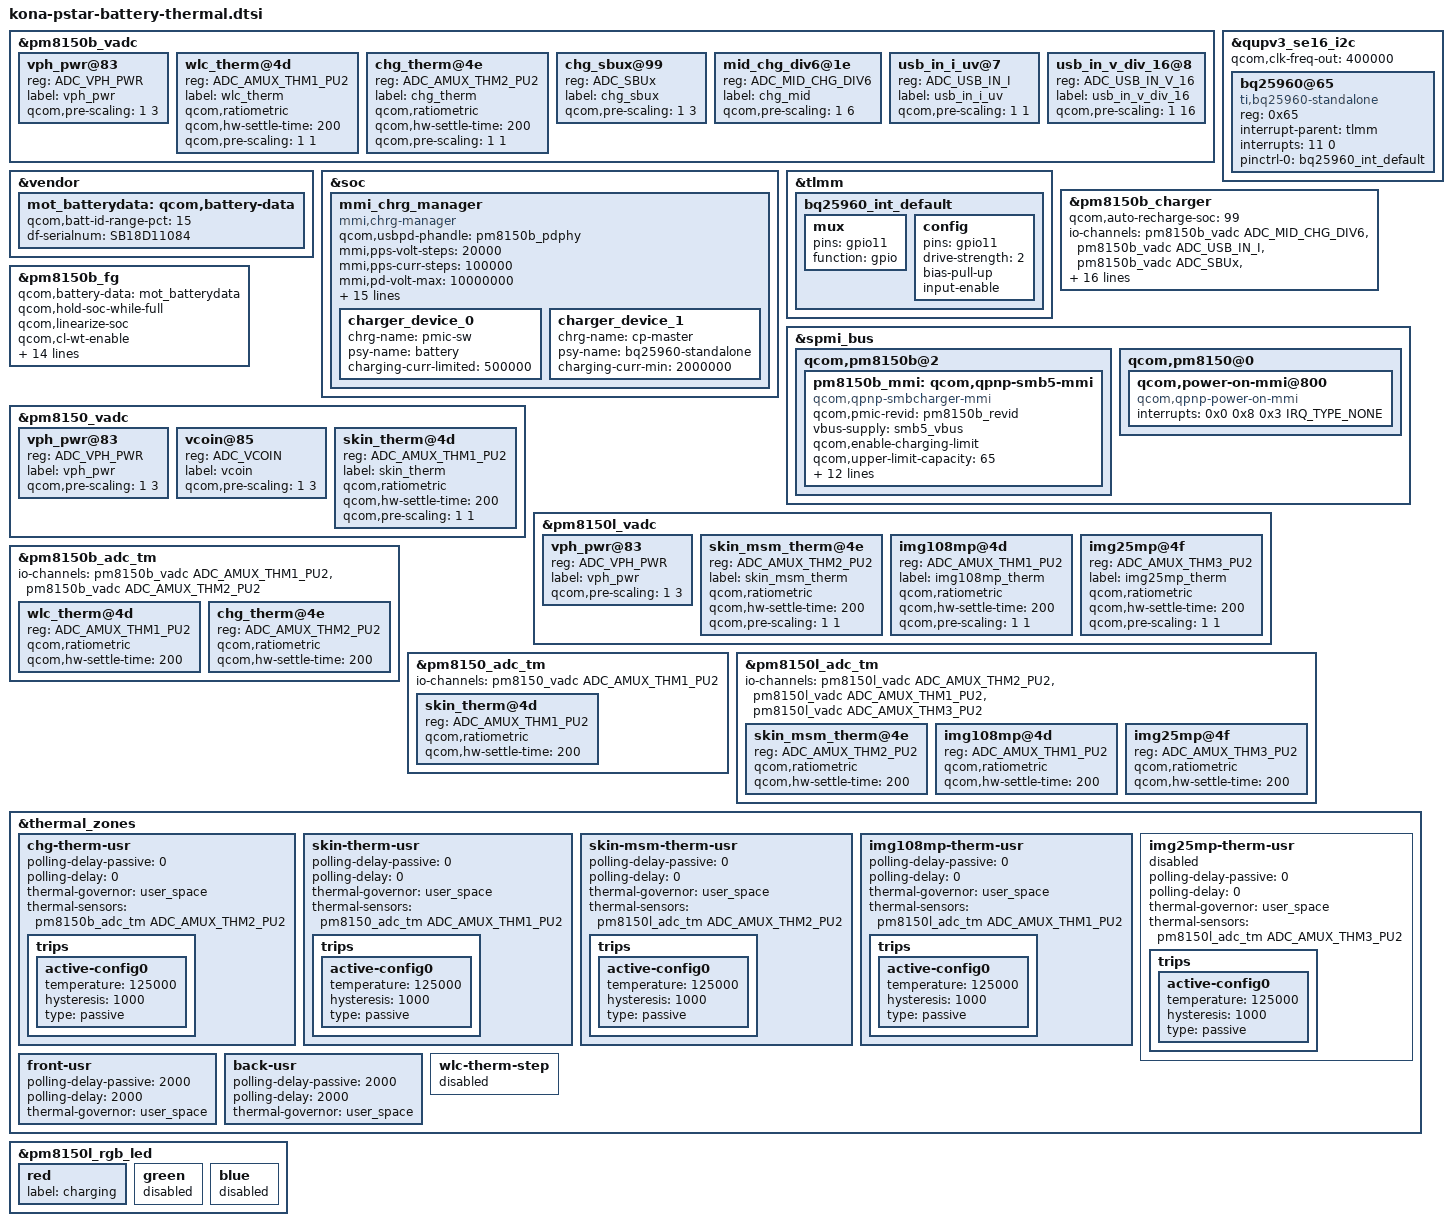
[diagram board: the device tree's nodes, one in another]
#include <dt-bindings/gpio/gpio.h>
#include <dt-bindings/pinctrl/qcom,pmic-gpio.h>

&pm8150b_vadc {
        #address-cells = <1>;
        #size-cells = <0>;

        vph_pwr@83 {
                reg = <ADC_VPH_PWR>;
                label = "vph_pwr";
                qcom,pre-scaling = <1 3>;
        };

        wlc_therm@4d {
                reg = <ADC_AMUX_THM1_PU2>;
                label = "wlc_therm";
                qcom,ratiometric;
                qcom,hw-settle-time = <200>;
                qcom,pre-scaling = <1 1>;
        };

        chg_therm@4e {
                reg = <ADC_AMUX_THM2_PU2>;
                label = "chg_therm";
                qcom,ratiometric;
                qcom,hw-settle-time = <200>;
                qcom,pre-scaling = <1 1>;
        };

        chg_sbux@99 {
                reg = <ADC_SBUx>;
                label = "chg_sbux";
                qcom,pre-scaling = <1 3>;
        };

        mid_chg_div6@1e {
                reg = <ADC_MID_CHG_DIV6>;
                label = "chg_mid";
                qcom,pre-scaling = <1 6>;
        };

        usb_in_i_uv@7 {
                reg = <ADC_USB_IN_I>;
                label = "usb_in_i_uv";
                qcom,pre-scaling = <1 1>;
        };

        usb_in_v_div_16@8 {
                reg = <ADC_USB_IN_V_16>;
                label = "usb_in_v_div_16";
                qcom,pre-scaling = <1 16>;
        };
};

&vendor {
        mot_batterydata: qcom,battery-data {
                qcom,batt-id-range-pct = <15>;
                df-serialnum = "SB18D11084";
		#include "fg-gen4-batterydata-MT45-4520mAh-Amperex.dtsi"
        };
};

&soc {
	mmi_chrg_manager {
		compatible = "mmi,chrg-manager";
		qcom,usbpd-phandle = <&pm8150b_pdphy>;
		mmi,pps-volt-steps = <20000>;
		mmi,pps-curr-steps = <100000>;
		mmi,pd-volt-max = <10000000>;
		mmi,pd-curr-max = <3000000>;
		mmi,batt-curr-boost = <300000>;
		mmi,batt-ovp-lmt = <4580000>;
		mmi,pl-chrg-vbatt-min = <3600000>;
		mmi,typec-middle-current = <1500000>;
		mmi,step-first-current-comp = <0>;
		mmi,dont-rerun-aicl;
		mmi,chrg-temp-zones-num = <5>;
		mmi,mmi-chrg-temp-zones =
					<0  4200 873  0 0 0 0>,
					<10 4250 2180 4480 873 0 0>,
					<15 4480 2180 0 0 0 0>,
					<45 4250 6000 4350 5200 4480 4000>,
					<60 4200 2180 0 0 0 0>;
		mmi,thermal-mitigation =
					<6000000>,
					<5000000>,
					<4000000>,
					<3000000>,
					<2000000>;
		charger_device_0 {
			chrg-name = "pmic-sw";
			psy-name = "battery";
			charging-curr-limited = <500000>;
		};
		charger_device_1 {
			chrg-name = "cp-master";
			psy-name = "bq25960-standalone";
			charging-curr-min = <2000000>;
		};
	};
};

&tlmm{
        bq25960_int_default: bq25960_int_default {
                mux {
                        pins = "gpio11";
                        function = "gpio";
                };

                config {
                        pins = "gpio11";
                        drive-strength = <2>; /* 2 MA */
                        bias-pull-up;
		//	bias_disable;
                        input-enable;
                };
        };
};

&qupv3_se16_i2c {
	status = "okay";
	qcom,clk-freq-out = <400000>;
	bq25960@65 {
		compatible = "ti,bq25960-standalone";
		reg = <0x65>;
		/delete-property/ interrupts;
                interrupt-parent = <&tlmm>;
                interrupts = <11 0>;
                interrupt-names = "bq25960_irq";
                pinctrl-names = "default";
                pinctrl-0 = <&bq25960_int_default>;
	};
};

&pm8150b_charger {
        status = "ok";
//        qcom,sec-charger-config = <0>;
        qcom,auto-recharge-soc = <99>;
        io-channels = <&pm8150b_vadc ADC_MID_CHG_DIV6>,
                      <&pm8150b_vadc ADC_USB_IN_I>,
                      <&pm8150b_vadc ADC_SBUx>,
                      <&pm8150b_vadc ADC_VPH_PWR>,
                      <&pm8150b_vadc ADC_CHG_TEMP>;
        io-channel-names = "mid_voltage",
                           "usb_in_current",
                           "sbux_res",
                           "vph_voltage",
                           "chg_temp";
        qcom,battery-data = <&mot_batterydata>;
        qcom,fcc-max-ua = <4000000>;
        qcom,fv-max-uv = <4480000>;
        qcom,usb-icl-ua = <3000000>;
        qcom,wd-bark-time-secs = <16>;
        qcom,suspend-input-on-debug-batt;
        qcom,usbpd-phandle = <&pm8150b_pdphy>;
        qcom,typec-legacy-rp-icl;
        qcom,disable-suspend-on-collapse;
	qcom,dc-unsupported;
	qcom,wireless-unsupported;
	qcom,usbeb-unsupported;
	qcom,thermal-mitigation = <4000000 3500000
				3000000 2500000
				2000000 1500000
				1200000 900000
				600000  400000>;
};

&spmi_bus {
        qcom,pm8150b@2 {
                pm8150b_mmi: qcom,qpnp-smb5-mmi {
                        compatible = "qcom,qpnp-smbcharger-mmi";
                        qcom,pmic-revid = <&pm8150b_revid>;
                        vbus-supply = <&smb5_vbus>;
                        status = "ok";
                        qcom,enable-charging-limit;
                        qcom,upper-limit-capacity = <65>;
                        qcom,lower-limit-capacity = <60>;
                        qcom,mmi-temp-zones =   <0  4200 873 0>,
                                                <10 4250 2180 873>,
                                                <15 0 2180 2180>,
						<23 0 4000 4000>,
						<35 0 4000 4000>,
                                                <45 0 4000 4000>,
                                                <60 4200 2180 0>;
                	qcom,mmi-ffc-zones = <4450 218 (-500)>,
                                        <4450 218 (-500)>,
                                        <4450 218 (-500)>,
                                        <4480 510 (-710)>,
                                        <4480 620 (-820)>,
                                        <4480 680 (-880)>,
                                        <4450 218 (-500)>;
                        qcom,iterm-ma = <218>;
                        qcom,vfloat-comp-uv = <20000>;
                        qcom,hvdcp-power-max = <20000>;
                };
        };

        qcom,pm8150@0 {
                qcom,power-on-mmi@800 {
                        compatible = "qcom,qpnp-power-on-mmi";
                        interrupts = <0x0 0x8 0x3 IRQ_TYPE_NONE>;
                        interrupt-names = "kpdpwr-bark";
                };
        };
};

&pm8150b_fg {
        status = "ok";
        qcom,battery-data = <&mot_batterydata>;
        qcom,hold-soc-while-full;
        qcom,linearize-soc;
        qcom,cl-wt-enable;
        qcom,fg-force-load-profile;
        /* ESR fast calibration */
        qcom,fg-esr-timer-chg-fast = <0 7>;
        qcom,fg-esr-timer-dischg-fast = <0 7>;
        qcom,fg-esr-timer-chg-slow = <0 96>;
        qcom,fg-esr-timer-dischg-slow = <0 96>;
        qcom,fg-esr-cal-soc-thresh = <26 230>;
        qcom,fg-esr-cal-temp-thresh = <10 40>;
        qcom,fg-cutoff-voltage = <3200>;
        qcom,fg-empty-voltage = <3000>;
        qcom,fg-sys-min-voltage = <3000>;
        qcom,fg-sys-term-current = <(-400)>;
        qcom,ki-coeff-low-chg = <1500>;
        qcom,ki-coeff-med-chg = <1500>;
        qcom,ki-coeff-hi-chg = <123>;
	/delete-property/qcom,rbat-conn-mohm;
	/*mmi,cp-use-internal-qg;*/
};

&pm8150_vadc {
        #address-cells = <1>;
        #size-cells = <0>;

        vph_pwr@83 {
                reg = <ADC_VPH_PWR>;
                label = "vph_pwr";
                qcom,pre-scaling = <1 3>;
        };

        vcoin@85 {
                reg = <ADC_VCOIN>;
                label = "vcoin";
                qcom,pre-scaling = <1 3>;
        };

        skin_therm@4d {
                reg = <ADC_AMUX_THM1_PU2>;
                label = "skin_therm";
                qcom,ratiometric;
                qcom,hw-settle-time = <200>;
                qcom,pre-scaling = <1 1>;
        };
};

&pm8150l_vadc {
        #address-cells = <1>;
        #size-cells = <0>;

        vph_pwr@83 {
                reg = <ADC_VPH_PWR>;
                label = "vph_pwr";
                qcom,pre-scaling = <1 3>;
        };

        skin_msm_therm@4e {
                reg = <ADC_AMUX_THM2_PU2>;
                label = "skin_msm_therm";
                qcom,ratiometric;
                qcom,hw-settle-time = <200>;
                qcom,pre-scaling = <1 1>;
        };

        img108mp@4d {
                reg = <ADC_AMUX_THM1_PU2>;
                label = "img108mp_therm";
                qcom,ratiometric;
                qcom,hw-settle-time = <200>;
                qcom,pre-scaling = <1 1>;
        };

        img25mp@4f {
                reg = <ADC_AMUX_THM3_PU2>;
                label = "img25mp_therm";
                qcom,ratiometric;
                qcom,hw-settle-time = <200>;
                qcom,pre-scaling = <1 1>;
        };
};

&pm8150b_adc_tm {
        #address-cells = <1>;
        #size-cells = <0>;

        io-channels = <&pm8150b_vadc ADC_AMUX_THM1_PU2>,
        <&pm8150b_vadc ADC_AMUX_THM2_PU2>;

        wlc_therm@4d {
                reg = <ADC_AMUX_THM1_PU2>;
                qcom,ratiometric;
                qcom,hw-settle-time = <200>;
        };

        chg_therm@4e {
                reg = <ADC_AMUX_THM2_PU2>;
                qcom,ratiometric;
                qcom,hw-settle-time = <200>;
        };
};

&pm8150_adc_tm {
        #address-cells = <1>;
        #size-cells = <0>;

        io-channels = <&pm8150_vadc ADC_AMUX_THM1_PU2>;

        skin_therm@4d {
                reg = <ADC_AMUX_THM1_PU2>;
                qcom,ratiometric;
                qcom,hw-settle-time = <200>;
        };
};

&pm8150l_adc_tm {
        #address-cells = <1>;
        #size-cells = <0>;

        io-channels = <&pm8150l_vadc ADC_AMUX_THM2_PU2>,
                        <&pm8150l_vadc ADC_AMUX_THM1_PU2>,
                        <&pm8150l_vadc ADC_AMUX_THM3_PU2>;

        skin_msm_therm@4e {
                reg = <ADC_AMUX_THM2_PU2>;
                qcom,ratiometric;
                qcom,hw-settle-time = <200>;
        };

        img108mp@4d {
                reg = <ADC_AMUX_THM1_PU2>;
                qcom,ratiometric;
                qcom,hw-settle-time = <200>;
        };

        img25mp@4f {
                reg = <ADC_AMUX_THM3_PU2>;
                qcom,ratiometric;
                qcom,hw-settle-time = <200>;
        };
};

&thermal_zones {
/*
        wlc-therm-step {
                polling-delay-passive = <0>;
                polling-delay = <0>;
                thermal-governor = "step_wise";
                thermal-sensors = <&pm8150b_adc_tm ADC_AMUX_THM1_PU2>;
                trips {
                        wlc_trip0: wlc-trip0 {
                                temperature = <50000>;
                                hysteresis = <3000>;
                                type = "passive";
                        };
                };
                cooling-maps {
                        wlc-trip-lvl0 {
                                trip = <&wlc_trip0>;
                                cooling-device = <&p938x_wls_i2c 1 1>;
                        };
                };
        };
*/
        chg-therm-usr {
                polling-delay-passive = <0>;
                polling-delay = <0>;
                thermal-governor = "user_space";
                thermal-sensors = <&pm8150b_adc_tm ADC_AMUX_THM2_PU2>;
                trips {
                        active-config0 {
                                temperature = <125000>;
                                hysteresis = <1000>;
                                type = "passive";
                        };
                };
        };

        skin-therm-usr {
                polling-delay-passive = <0>;
                polling-delay = <0>;
                thermal-governor = "user_space";
                thermal-sensors = <&pm8150_adc_tm ADC_AMUX_THM1_PU2>;
                trips {
                        active-config0 {
                                temperature = <125000>;
                                hysteresis = <1000>;
                                type = "passive";
                        };
                };
        };

        skin-msm-therm-usr {
                polling-delay-passive = <0>;
                polling-delay = <0>;
                thermal-governor = "user_space";
                thermal-sensors = <&pm8150l_adc_tm ADC_AMUX_THM2_PU2>;
                trips {
                        active-config0 {
                                temperature = <125000>;
                                hysteresis = <1000>;
                                type = "passive";
                        };
                };
        };

        img108mp-therm-usr {
                polling-delay-passive = <0>;
                polling-delay = <0>;
                thermal-governor = "user_space";
                thermal-sensors = <&pm8150l_adc_tm ADC_AMUX_THM1_PU2>;
                trips {
                        active-config0 {
                                temperature = <125000>;
                                hysteresis = <1000>;
                                type = "passive";
                        };
                };
        };

        img25mp-therm-usr {
                polling-delay-passive = <0>;
                polling-delay = <0>;
                thermal-governor = "user_space";
                thermal-sensors = <&pm8150l_adc_tm ADC_AMUX_THM3_PU2>;
                trips {
                        active-config0 {
                                temperature = <125000>;
                                hysteresis = <1000>;
                                type = "passive";
                        };
                };
        };
/*
        mmw0-surface-step {
                polling-delay-passive = <2000>;
                polling-delay = <2000>;
                thermal-governor = "step_wise";
                trips {
                        modem_skin0_trip0: modem-skin0-trip0 {
                                temperature = <48000>;
                                hysteresis = <5000>;
                                type = "passive";
                        };
                };
                cooling-maps {
                        skin0_modem_lvl2 {
                                trip = <&modem_skin0_trip0>;
                                cooling-device = <&modem_mmw0 2 2>;
                        };
                };
        };

        mmw1-surface-step {
                polling-delay-passive = <2000>;
                polling-delay = <2000>;
                thermal-governor = "step_wise";
                trips {
                        modem_skin1_trip0: modem-skin1-trip0 {
                                temperature = <48000>;
                                hysteresis = <5000>;
                                type = "passive";
                        };
                };
                cooling-maps {
                        skin1_modem_lvl2 {
                                trip = <&modem_skin1_trip0>;
                                cooling-device = <&modem_mmw1 2 2>;
                        };
                };
        };

        sdx55-surface-step {
                polling-delay-passive = <2000>;
                polling-delay = <2000>;
                thermal-governor = "step_wise";
                trips {
                        modem_skin_trip1: modem-skin-trip1 {
                                temperature = <44000>;
                                hysteresis = <2000>;
                                type = "passive";
                        };
                        modem_skin_trip2: modem-skin-trip2 {
                                temperature = <47000>;
                                hysteresis = <3000>;
                                type = "passive";
                        };
                };
                cooling-maps {
                        modem_skin_l1 {
                                trip = <&modem_skin_trip1>;
                                cooling-device = <&modem_skin 1 1>;
                        };
                        modem_skin_l2 {
                                trip = <&modem_skin_trip2>;
                                cooling-device = <&modem_skin 2 2>;
                        };
                };

        };
*/
        front-usr {
                polling-delay-passive = <2000>;
                polling-delay = <2000>;
                thermal-governor = "user_space";
        };

        back-usr {
                polling-delay-passive = <2000>;
                polling-delay = <2000>;
                thermal-governor = "user_space";
        };
};

/*
&thermal_zones {
        soc {
                trips {
                        soc_trip2:soc-trip2 {
                                temperature = <15>;
                                hysteresis = <0>;
                                type = "passive";
                        };
                };
                cooling-maps {
                        soc_modem {
                                trip = <&soc_trip2>;
                                cooling-device = <&modem_mmw0 3 3>;
                        };
                };
        };
};
*/

&pm8150l_rgb_led {
        red {
                label = "charging";
        };

        green {
                status = "disabled";
        };

        blue {
                status = "disabled";
        };
};

&thermal_zones {
	wlc-therm-step {
		status = "disabled";
	};

	img25mp-therm-usr {
                status = "disabled";
        };
};

